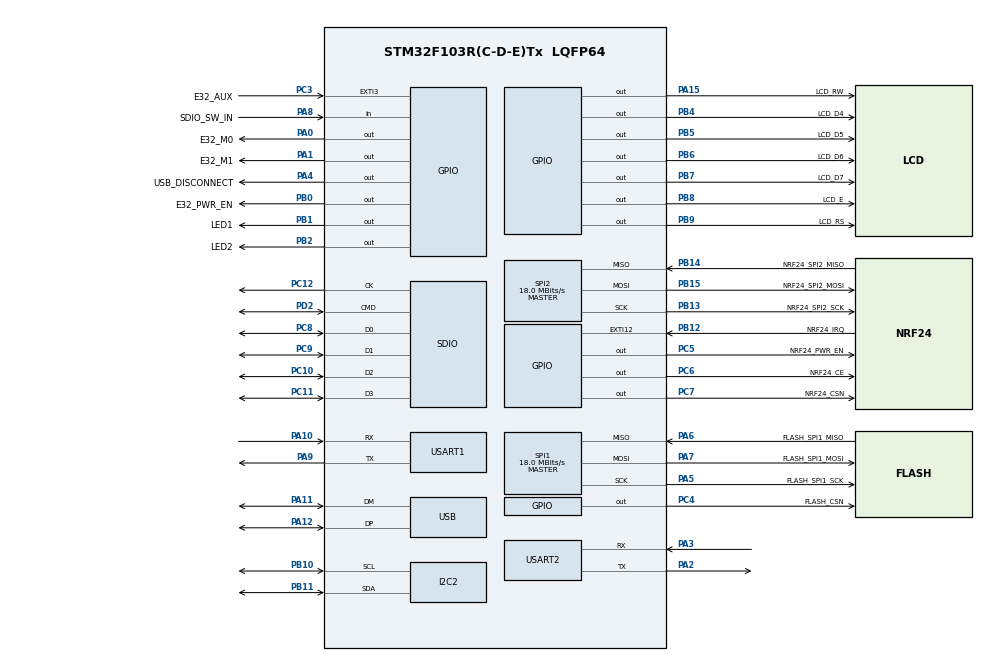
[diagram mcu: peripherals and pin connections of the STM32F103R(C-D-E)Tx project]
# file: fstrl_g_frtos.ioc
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Dma.MEMTOMEM.2.Direction=DMA_MEMORY_TO_MEMORY
Dma.MEMTOMEM.2.Instance=DMA1_Channel1
Dma.MEMTOMEM.2.MemDataAlignment=DMA_MDATAALIGN_WORD
Dma.MEMTOMEM.2.MemInc=DMA_MINC_ENABLE
Dma.MEMTOMEM.2.Mode=DMA_NORMAL
Dma.MEMTOMEM.2.PeriphDataAlignment=DMA_PDATAALIGN_WORD
Dma.MEMTOMEM.2.PeriphInc=DMA_PINC_ENABLE
Dma.MEMTOMEM.2.Priority=DMA_PRIORITY_MEDIUM
Dma.MEMTOMEM.3.Direction=DMA_MEMORY_TO_MEMORY
Dma.MEMTOMEM.3.Instance=DMA2_Channel1
Dma.MEMTOMEM.3.MemDataAlignment=DMA_MDATAALIGN_BYTE
Dma.MEMTOMEM.3.MemInc=DMA_MINC_ENABLE
Dma.MEMTOMEM.3.Mode=DMA_NORMAL
Dma.MEMTOMEM.3.PeriphDataAlignment=DMA_PDATAALIGN_BYTE
Dma.MEMTOMEM.3.PeriphInc=DMA_PINC_ENABLE
Dma.MEMTOMEM.3.Priority=DMA_PRIORITY_MEDIUM
Dma.Request0=SPI1_RX
Dma.Request1=SPI1_TX
Dma.Request2=MEMTOMEM
Dma.Request3=MEMTOMEM
Dma.Request4=USART1_RX
Dma.Request5=USART1_TX
Dma.Request6=USART2_RX
Dma.Request7=USART2_TX
Dma.Request8=SDIO
Dma.SDIO.8.Direction=DMA_PERIPH_TO_MEMORY
Dma.SDIO.8.Instance=DMA2_Channel4
Dma.SDIO.8.MemDataAlignment=DMA_MDATAALIGN_WORD
Dma.SDIO.8.MemInc=DMA_MINC_ENABLE
Dma.SDIO.8.Mode=DMA_NORMAL
Dma.SDIO.8.PeriphDataAlignment=DMA_PDATAALIGN_WORD
Dma.SDIO.8.PeriphInc=DMA_PINC_DISABLE
Dma.SDIO.8.Priority=DMA_PRIORITY_MEDIUM
Dma.SPI1_RX.0.Direction=DMA_PERIPH_TO_MEMORY
Dma.SPI1_RX.0.Instance=DMA1_Channel2
Dma.SPI1_RX.0.MemDataAlignment=DMA_MDATAALIGN_BYTE
Dma.SPI1_RX.0.MemInc=DMA_MINC_ENABLE
Dma.SPI1_RX.0.Mode=DMA_NORMAL
Dma.SPI1_RX.0.PeriphDataAlignment=DMA_PDATAALIGN_BYTE
Dma.SPI1_RX.0.PeriphInc=DMA_PINC_DISABLE
Dma.SPI1_RX.0.Priority=DMA_PRIORITY_VERY_HIGH
Dma.SPI1_TX.1.Direction=DMA_MEMORY_TO_PERIPH
Dma.SPI1_TX.1.Instance=DMA1_Channel3
Dma.SPI1_TX.1.MemDataAlignment=DMA_MDATAALIGN_BYTE
Dma.SPI1_TX.1.MemInc=DMA_MINC_ENABLE
Dma.SPI1_TX.1.Mode=DMA_NORMAL
Dma.SPI1_TX.1.PeriphDataAlignment=DMA_PDATAALIGN_BYTE
Dma.SPI1_TX.1.PeriphInc=DMA_PINC_DISABLE
Dma.SPI1_TX.1.Priority=DMA_PRIORITY_VERY_HIGH
Dma.USART1_RX.4.Direction=DMA_PERIPH_TO_MEMORY
Dma.USART1_RX.4.Instance=DMA1_Channel5
Dma.USART1_RX.4.MemDataAlignment=DMA_MDATAALIGN_BYTE
Dma.USART1_RX.4.MemInc=DMA_MINC_ENABLE
Dma.USART1_RX.4.Mode=DMA_NORMAL
Dma.USART1_RX.4.PeriphDataAlignment=DMA_PDATAALIGN_BYTE
Dma.USART1_RX.4.PeriphInc=DMA_PINC_DISABLE
Dma.USART1_RX.4.Priority=DMA_PRIORITY_LOW
Dma.USART1_TX.5.Direction=DMA_MEMORY_TO_PERIPH
Dma.USART1_TX.5.Instance=DMA1_Channel4
Dma.USART1_TX.5.MemDataAlignment=DMA_MDATAALIGN_BYTE
Dma.USART1_TX.5.MemInc=DMA_MINC_ENABLE
Dma.USART1_TX.5.Mode=DMA_NORMAL
Dma.USART1_TX.5.PeriphDataAlignment=DMA_PDATAALIGN_BYTE
Dma.USART1_TX.5.PeriphInc=DMA_PINC_DISABLE
Dma.USART1_TX.5.Priority=DMA_PRIORITY_LOW
Dma.USART2_RX.6.Direction=DMA_PERIPH_TO_MEMORY
Dma.USART2_RX.6.Instance=DMA1_Channel6
Dma.USART2_RX.6.MemDataAlignment=DMA_MDATAALIGN_BYTE
Dma.USART2_RX.6.MemInc=DMA_MINC_ENABLE
Dma.USART2_RX.6.Mode=DMA_NORMAL
Dma.USART2_RX.6.PeriphDataAlignment=DMA_PDATAALIGN_BYTE
Dma.USART2_RX.6.PeriphInc=DMA_PINC_DISABLE
Dma.USART2_RX.6.Priority=DMA_PRIORITY_LOW
Dma.USART2_TX.7.Direction=DMA_MEMORY_TO_PERIPH
Dma.USART2_TX.7.Instance=DMA1_Channel7
Dma.USART2_TX.7.MemDataAlignment=DMA_MDATAALIGN_BYTE
Dma.USART2_TX.7.MemInc=DMA_MINC_ENABLE
Dma.USART2_TX.7.Mode=DMA_NORMAL
Dma.USART2_TX.7.PeriphDataAlignment=DMA_PDATAALIGN_BYTE
Dma.USART2_TX.7.PeriphInc=DMA_PINC_DISABLE
Dma.USART2_TX.7.Priority=DMA_PRIORITY_LOW
FATFS.BSP.number=1
FATFS._FS_LOCK=4
FATFS._FS_RPATH=2
FATFS._USE_FIND=1
FATFS._VOLUMES=1
FATFS0.BSP.STBoard=false
FATFS0.BSP.api=Unknown
FATFS0.BSP.i2caddr=0
FATFS0.BSP.instance=PA8
FATFS0.BSP.ip=GPIO
FATFS0.BSP.mode=Input
FATFS0.BSP.name=Detect_SDIO
FATFS0.BSP.solution=PA8
FREERTOS.INCLUDE_eTaskGetState=1
FREERTOS.INCLUDE_pcTaskGetTaskName=1
FREERTOS.INCLUDE_uxTaskGetStackHighWaterMark=1
FREERTOS.INCLUDE_vTaskCleanUpResources=1
FREERTOS.INCLUDE_vTaskDelayUntil=1
FREERTOS.INCLUDE_xEventGroupSetBitFromISR=1
FREERTOS.INCLUDE_xQueueGetMutexHolder=1
FREERTOS.INCLUDE_xSemaphoreGetMutexHolder=1
FREERTOS.INCLUDE_xTaskAbortDelay=1
FREERTOS.INCLUDE_xTaskGetCurrentTaskHandle=1
FREERTOS.INCLUDE_xTaskGetHandle=1
FREERTOS.INCLUDE_xTimerPendFunctionCall=1
FREERTOS.MEMORY_ALLOCATION=2
FREERTOS.Mutexes01=mt_SPI1_free,Static,mt_SPI1_freeControlBlock;mt_SPI2_free,Static,mt_SPI2_freeControlBlock;mt_LCD_free,Static,mt_LCD_freeControlBlock;mt_UART1_free,Static,mt_UART1_freeControlBlock;mt_UART2_free,Static,mt_UART2_freeControlBlock;mt_NAND_FLASH,Static,mt_NAND_FLASHControlBlock
FREERTOS.Queues01=msgto_tsk_SpiNand_io,16,uint8_t,0,Static,msgto_SpiNand_wrkrBuffer,msgto_SpiNand_wrkrControlBlock;msgto_gkt_LCD,16,lcd_msg,0,Static,msgto_gkt_LCDBuffer,msgto_gkt_LCDControlBlock
FREERTOS.Tasks01=tsk_INIT_Periph,1,256,vStart_tsk_INIT_Periph,As weak,NULL,Static,tsk_INIT_PeriphBuffer,tsk_INIT_PeriphControlBlock;tsk_SPINand_io,0,1024,vStart_tsk_SPINand_io,As weak,NULL,Static,tsk_SPINand_ioBuffer,tsk_SPINand_ioControlBlock;tsk_LED1_blink,0,256,vStart_tsk_LEDx_blink,As weak,NULL,Static,tsk_LED1_blinkBuffer,tsk_LED1_blinkControlBlock;tsk_LED2_blink,0,256,vStart_tsk_LEDx_blink,As weak,1,Static,tsk_LED2_blinkBuffer,tsk_LED2_blinkControlBlock;gkt_LCD,0,256,vStart_gkt_LCD,As weak,NULL,Static,gkt_LCDBuffer,gkt_LCDControlBlock
FREERTOS.Timers01=tmTestTimer,tmTestTimer_clbck,osTimerPeriodic,Default,NULL,Static,tmTestTimerControlBlock
FREERTOS.configENABLE_BACKWARD_COMPATIBILITY=0
FREERTOS.configGENERATE_RUN_TIME_STATS=1
FREERTOS.configMAX_PRIORITIES=7
FREERTOS.configMAX_TASK_NAME_LEN=32
FREERTOS.configMINIMAL_STACK_SIZE=128
FREERTOS.configQUEUE_REGISTRY_SIZE=255
FREERTOS.configTIMER_TASK_PRIORITY=5
FREERTOS.configTOTAL_HEAP_SIZE=10240
FREERTOS.configUSE_APPLICATION_TASK_TAG=1
FREERTOS.configUSE_COUNTING_SEMAPHORES=1
FREERTOS.configUSE_MALLOC_FAILED_HOOK=1
FREERTOS.configUSE_STATS_FORMATTING_FUNCTIONS=1
FREERTOS.configUSE_TIMERS=1
FREERTOS.configUSE_TRACE_FACILITY=1
I2C2.I2C_Mode=I2C_Fast
Mcu.Family=STM32F1
Mcu.Name=STM32F103R(C-D-E)Tx
Mcu.Package=LQFP64
NVIC.DMA1_Channel1_IRQn=true\:5\:0\:false\:false\:true\:true\:true\:true
NVIC.DMA1_Channel2_IRQn=true\:5\:0\:false\:false\:true\:true\:false\:true
NVIC.DMA1_Channel3_IRQn=true\:5\:0\:false\:false\:true\:true\:false\:true
NVIC.DMA1_Channel4_IRQn=true\:5\:0\:false\:false\:true\:true\:false\:true
NVIC.DMA1_Channel5_IRQn=true\:5\:0\:false\:false\:true\:true\:false\:true
NVIC.DMA1_Channel6_IRQn=true\:5\:0\:false\:false\:true\:true\:false\:true
NVIC.DMA1_Channel7_IRQn=true\:5\:0\:false\:false\:true\:true\:false\:true
NVIC.DMA2_Channel1_IRQn=true\:5\:0\:false\:false\:true\:true\:true\:true
NVIC.DMA2_Channel4_5_IRQn=true\:5\:0\:false\:false\:true\:true\:false\:true
NVIC.PriorityGroup=NVIC_PRIORITYGROUP_4
NVIC.RCC_IRQn=true\:5\:0\:false\:false\:true\:true\:true\:false
NVIC.SDIO_IRQn=true\:5\:0\:false\:false\:true\:true\:true\:true
NVIC.TIM6_IRQn=true\:0\:0\:false\:false\:true\:false\:true\:true
NVIC.TIM7_IRQn=true\:5\:0\:true\:false\:true\:true\:true\:true
NVIC.TimeBase=TIM6_IRQn
NVIC.TimeBaseIP=TIM6
NVIC.USART1_IRQn=true\:5\:0\:true\:false\:true\:true\:true\:true
NVIC.USART2_IRQn=true\:5\:0\:true\:false\:true\:true\:true\:true
NVIC.USB_LP_CAN1_RX0_IRQn=true\:5\:0\:false\:false\:true\:true\:false\:true
PA0-WKUP.GPIO_Label=E32_M0
PA0-WKUP.GPIO_ModeDefaultOutputPP=GPIO_MODE_OUTPUT_PP
PA0-WKUP.GPIO_PuPd=GPIO_NOPULL
PA0-WKUP.GPIO_Speed=GPIO_SPEED_FREQ_LOW
PA0-WKUP.PinState=GPIO_PIN_RESET
PA0-WKUP.Signal=GPIO_Output
PA1.GPIO_Label=E32_M1
PA1.GPIO_ModeDefaultOutputPP=GPIO_MODE_OUTPUT_PP
PA1.GPIO_PuPd=GPIO_NOPULL
PA1.GPIO_Speed=GPIO_SPEED_FREQ_LOW
PA1.PinState=GPIO_PIN_RESET
PA1.Signal=GPIO_Output
PA10.Mode=Asynchronous
PA10.Signal=USART1_RX
PA11.Mode=Device
PA11.Signal=USB_DM
PA12.Mode=Device
PA12.Signal=USB_DP
PA13.Mode=Trace_Asynchronous_SW
PA13.Signal=SYS_JTMS-SWDIO
PA14.Mode=Trace_Asynchronous_SW
PA14.Signal=SYS_JTCK-SWCLK
PA15.GPIO_Label=LCD_RW
PA15.GPIO_ModeDefaultOutputPP=GPIO_MODE_OUTPUT_PP
PA15.GPIO_PuPd=GPIO_NOPULL
PA15.GPIO_Speed=GPIO_SPEED_FREQ_HIGH
PA15.PinState=GPIO_PIN_RESET
PA15.Signal=GPIO_Output
PA2.GPIO_Mode=GPIO_MODE_AF_PP
PA2.GPIO_Speed=GPIO_SPEED_FREQ_HIGH
PA2.Mode=Asynchronous
PA2.Signal=USART2_TX
PA3.GPIO_Mode=GPIO_MODE_INPUT
PA3.GPIO_PuPd=GPIO_NOPULL
PA3.Mode=Asynchronous
PA3.Signal=USART2_RX
PA4.GPIO_Label=USB_DISCONNECT
PA4.GPIO_ModeDefaultOutputPP=GPIO_MODE_OUTPUT_OD
PA4.GPIO_PuPd=GPIO_PULLUP
PA4.GPIO_Speed=GPIO_SPEED_FREQ_HIGH
PA4.PinState=GPIO_PIN_SET
PA4.Signal=GPIO_Output
PA5.GPIO_Label=FLASH_SPI1_SCK
PA5.GPIO_Mode=GPIO_MODE_AF_PP
PA5.GPIO_Speed=GPIO_SPEED_FREQ_HIGH
PA5.Mode=Full_Duplex_Master
PA5.Signal=SPI1_SCK
PA6.GPIO_Label=FLASH_SPI1_MISO
PA6.GPIO_Mode=GPIO_MODE_INPUT
PA6.GPIO_PuPd=GPIO_NOPULL
PA6.Mode=Full_Duplex_Master
PA6.Signal=SPI1_MISO
PA7.GPIO_Label=FLASH_SPI1_MOSI
PA7.GPIO_Mode=GPIO_MODE_AF_PP
PA7.GPIO_Speed=GPIO_SPEED_FREQ_HIGH
PA7.Mode=Full_Duplex_Master
PA7.Signal=SPI1_MOSI
PA8.GPIO_Label=SDIO_SW_IN
PA8.GPIO_Mode=GPIO_MODE_INPUT
PA8.GPIO_PuPd=GPIO_PULLUP
PA8.Signal=GPIO_Input
PA9.Mode=Asynchronous
PA9.Signal=USART1_TX
PB0.GPIO_Label=E32_PWR_EN
PB0.GPIO_ModeDefaultOutputPP=GPIO_MODE_OUTPUT_PP
PB0.GPIO_PuPd=GPIO_NOPULL
PB0.GPIO_Speed=GPIO_SPEED_FREQ_LOW
PB0.PinState=GPIO_PIN_RESET
PB0.Signal=GPIO_Output
PB1.GPIO_Label=LED1
PB1.GPIO_ModeDefaultOutputPP=GPIO_MODE_OUTPUT_PP
PB1.GPIO_PuPd=GPIO_NOPULL
PB1.GPIO_Speed=GPIO_SPEED_FREQ_LOW
PB1.PinState=GPIO_PIN_SET
PB1.Signal=GPIO_Output
PB10.Mode=I2C
PB10.Signal=I2C2_SCL
PB11.Mode=I2C
PB11.Signal=I2C2_SDA
PB12.GPIO_Label=NRF24_IRQ
PB12.GPIO_ModeDefaultEXTI=GPIO_MODE_IT_RISING
PB12.GPIO_PuPd=GPIO_NOPULL
PB12.Signal=GPXTI12
PB13.GPIO_Label=NRF24_SPI2_SCK
PB13.GPIO_Mode=GPIO_MODE_AF_PP
PB13.GPIO_Speed=GPIO_SPEED_FREQ_HIGH
PB13.Mode=Full_Duplex_Master
PB13.Signal=SPI2_SCK
PB14.GPIO_Label=NRF24_SPI2_MISO
PB14.GPIO_Mode=GPIO_MODE_INPUT
PB14.GPIO_PuPd=GPIO_NOPULL
PB14.Mode=Full_Duplex_Master
PB14.Signal=SPI2_MISO
PB15.GPIO_Label=NRF24_SPI2_MOSI
PB15.GPIO_Mode=GPIO_MODE_AF_PP
PB15.GPIO_Speed=GPIO_SPEED_FREQ_HIGH
PB15.Mode=Full_Duplex_Master
PB15.Signal=SPI2_MOSI
PB2.GPIO_Label=LED2
PB2.GPIO_ModeDefaultOutputPP=GPIO_MODE_OUTPUT_PP
PB2.GPIO_PuPd=GPIO_NOPULL
PB2.GPIO_Speed=GPIO_SPEED_FREQ_LOW
PB2.PinState=GPIO_PIN_RESET
PB2.Signal=GPIO_Output
PB3.Mode=Trace_Asynchronous_SW
PB3.Signal=SYS_JTDO-TRACESWO
PB4.GPIO_Label=LCD_D4
PB4.GPIO_ModeDefaultOutputPP=GPIO_MODE_OUTPUT_PP
PB4.GPIO_PuPd=GPIO_NOPULL
PB4.GPIO_Speed=GPIO_SPEED_FREQ_HIGH
PB4.PinState=GPIO_PIN_RESET
PB4.Signal=GPIO_Output
PB5.GPIO_Label=LCD_D5
PB5.GPIO_ModeDefaultOutputPP=GPIO_MODE_OUTPUT_PP
PB5.GPIO_PuPd=GPIO_NOPULL
PB5.GPIO_Speed=GPIO_SPEED_FREQ_HIGH
PB5.PinState=GPIO_PIN_RESET
PB5.Signal=GPIO_Output
PB6.GPIO_Label=LCD_D6
PB6.GPIO_ModeDefaultOutputPP=GPIO_MODE_OUTPUT_PP
PB6.GPIO_PuPd=GPIO_NOPULL
PB6.GPIO_Speed=GPIO_SPEED_FREQ_HIGH
PB6.PinState=GPIO_PIN_RESET
PB6.Signal=GPIO_Output
PB7.GPIO_Label=LCD_D7
PB7.GPIO_ModeDefaultOutputPP=GPIO_MODE_OUTPUT_PP
PB7.GPIO_PuPd=GPIO_NOPULL
PB7.GPIO_Speed=GPIO_SPEED_FREQ_HIGH
PB7.PinState=GPIO_PIN_RESET
PB7.Signal=GPIO_Output
PB8.GPIO_Label=LCD_E
PB8.GPIO_ModeDefaultOutputPP=GPIO_MODE_OUTPUT_PP
PB8.GPIO_PuPd=GPIO_NOPULL
PB8.GPIO_Speed=GPIO_SPEED_FREQ_HIGH
PB8.PinState=GPIO_PIN_RESET
PB8.Signal=GPIO_Output
PB9.GPIO_Label=LCD_RS
PB9.GPIO_ModeDefaultOutputPP=GPIO_MODE_OUTPUT_PP
PB9.GPIO_PuPd=GPIO_NOPULL
PB9.GPIO_Speed=GPIO_SPEED_FREQ_HIGH
PB9.PinState=GPIO_PIN_RESET
PB9.Signal=GPIO_Output
PC10.Mode=SD_4_bits_Wide_bus
PC10.Signal=SDIO_D2
PC11.Mode=SD_4_bits_Wide_bus
PC11.Signal=SDIO_D3
PC12.Mode=SD_4_bits_Wide_bus
PC12.Signal=SDIO_CK
PC14-OSC32_IN.Mode=LSE-External-Oscillator
PC14-OSC32_IN.Signal=RCC_OSC32_IN
PC15-OSC32_OUT.Mode=LSE-External-Oscillator
PC15-OSC32_OUT.Signal=RCC_OSC32_OUT
PC3.GPIO_Label=E32_AUX
PC3.GPIO_ModeDefaultEXTI=GPIO_MODE_IT_RISING
PC3.GPIO_PuPd=GPIO_NOPULL
PC3.Signal=GPXTI3
PC4.GPIO_Label=FLASH_CSN
PC4.GPIO_ModeDefaultOutputPP=GPIO_MODE_OUTPUT_PP
PC4.GPIO_PuPd=GPIO_NOPULL
PC4.GPIO_Speed=GPIO_SPEED_FREQ_HIGH
PC4.PinState=GPIO_PIN_SET
PC4.Signal=GPIO_Output
PC5.GPIO_Label=NRF24_PWR_EN
PC5.GPIO_ModeDefaultOutputPP=GPIO_MODE_OUTPUT_PP
PC5.GPIO_PuPd=GPIO_NOPULL
PC5.GPIO_Speed=GPIO_SPEED_FREQ_MEDIUM
PC5.PinState=GPIO_PIN_RESET
PC5.Signal=GPIO_Output
PC6.GPIO_Label=NRF24_CE
PC6.GPIO_ModeDefaultOutputPP=GPIO_MODE_OUTPUT_PP
PC6.GPIO_PuPd=GPIO_NOPULL
PC6.GPIO_Speed=GPIO_SPEED_FREQ_MEDIUM
PC6.PinState=GPIO_PIN_SET
PC6.Signal=GPIO_Output
PC7.GPIO_Label=NRF24_CSN
PC7.GPIO_ModeDefaultOutputPP=GPIO_MODE_OUTPUT_PP
PC7.GPIO_PuPd=GPIO_NOPULL
PC7.GPIO_Speed=GPIO_SPEED_FREQ_MEDIUM
PC7.PinState=GPIO_PIN_RESET
PC7.Signal=GPIO_Output
PC8.Mode=SD_4_bits_Wide_bus
PC8.Signal=SDIO_D0
PC9.Mode=SD_4_bits_Wide_bus
PC9.Signal=SDIO_D1
PD0-OSC_IN.Mode=HSE-External-Oscillator
PD0-OSC_IN.Signal=RCC_OSC_IN
PD1-OSC_OUT.Mode=HSE-External-Oscillator
PD1-OSC_OUT.Signal=RCC_OSC_OUT
PD2.Mode=SD_4_bits_Wide_bus
PD2.Signal=SDIO_CMD
ProjectManager.HeapSize=0x2000
ProjectManager.StackSize=0x1000
ProjectManager.TargetToolchain=STM32CubeIDE
RCC.AHBFreq_Value=72000000
RCC.APB1CLKDivider=RCC_HCLK_DIV2
RCC.APB1Freq_Value=36000000
RCC.APB1TimFreq_Value=72000000
RCC.APB2Freq_Value=72000000
RCC.APB2TimFreq_Value=72000000
RCC.EnbaleCSS=true
RCC.HCLKFreq_Value=72000000
RCC.HSE_VALUE=12000000
RCC.PLLMUL=RCC_PLL_MUL6
RCC.PLLSourceVirtual=RCC_PLLSOURCE_HSE
RCC.RTCClockSelection=RCC_RTCCLKSOURCE_LSE
RCC.SYSCLKFreq_VALUE=72000000
RCC.SYSCLKSource=RCC_SYSCLKSOURCE_PLLCLK
RCC.USBFreq_Value=48000000
RCC.USBPrescaler=RCC_USBCLKSOURCE_PLL_DIV1_5
RTC.Date=19
RTC.Month=RTC_MONTH_AUGUST
RTC.OutPut=RTC_OUTPUTSOURCE_SECOND
RTC.WeekDay=RTC_WEEKDAY_FRIDAY
RTC.Year=14
SDIO.ClockBypass=SDIO_CLOCK_BYPASS_DISABLE
SDIO.ClockDiv=4
SDIO.ClockPowerSave=SDIO_CLOCK_POWER_SAVE_DISABLE
SDIO.HardwareFlowControl=SDIO_HARDWARE_FLOW_CONTROL_DISABLE
SPI1.BaudRatePrescaler=SPI_BAUDRATEPRESCALER_4
SPI1.CalculateBaudRate=18.0 MBits/s
SPI1.Direction=SPI_DIRECTION_2LINES
SPI1.Mode=SPI_MODE_MASTER
SPI1.VirtualType=VM_MASTER
SPI2.BaudRatePrescaler=SPI_BAUDRATEPRESCALER_2
SPI2.CalculateBaudRate=18.0 MBits/s
SPI2.Direction=SPI_DIRECTION_2LINES
SPI2.Mode=SPI_MODE_MASTER
SPI2.VirtualType=VM_MASTER
TIM7.Period=0xFFFF
TIM7.Prescaler=((SystemCoreClock/1000000) - 1)
TIM7.TIM_MasterOutputTrigger=TIM_TRGO_UPDATE
USART1.VirtualMode=VM_ASYNC
USART2.VirtualMode=VM_ASYNC
USB.low_power_enable=DISABLE
USB.lpm_enable=DISABLE
USB_DEVICE.CLASS_NAME_FS=MSC
USB_DEVICE.MANUFACTURER_STRING=FSTRL
USB_DEVICE.PRODUCT_STRING_MSC_FS=FSTRL Mass Storage
USB_DEVICE.USBD_DEBUG_LEVEL=0
USB_DEVICE.USBD_MAX_NUM_CONFIGURATION=1
USB_DEVICE.USBD_MAX_NUM_INTERFACES=1
USB_DEVICE.USBD_SELF_POWERED=0
USB_DEVICE.VirtualMode=Msc
USB_DEVICE.VirtualModeFS=Msc_FS
VP_CRC_VS_CRC.Mode=CRC_Activate
VP_FATFS_VS_SDIO.Mode=SDIO
VP_FREERTOS_VS_CMSIS_V1.Mode=CMSIS_V1
VP_RTC_VS_RTC_Activate.Mode=RTC_Enabled
VP_RTC_VS_RTC_Calendar.Mode=RTC_Calendar
VP_SYS_VS_tim6.Mode=TIM6
VP_TIM7_VS_ClockSourceINT.Mode=Enable_Timer
VP_TIM7_VS_OPM.Mode=OPM_bit
VP_USB_DEVICE_VS_USB_DEVICE_MSC_FS.Mode=MSC_FS
board=custom

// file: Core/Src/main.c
/* USER CODE BEGIN Header */
/**
  ******************************************************************************
  * @file           : main.c
  * @brief          : Main program body
  ******************************************************************************
  * @attention
  *
  * <h2><center>&copy; Copyright (c) 2019 STMicroelectronics.
  * All rights reserved.</center></h2>
  *
  * This software component is licensed by ST under Ultimate Liberty license
  * SLA0044, the "License"; You may not use this file except in compliance with
  * the License. You may obtain a copy of the License at:
  *                             www.st.com/SLA0044
  *
  ******************************************************************************
  */
/* USER CODE END Header */

#include "main.h"
#include "cmsis_os.h"
#include "crc.h"
#include "dma.h"
#include "fatfs.h"
#include "i2c.h"
#include "rtc.h"
#include "sdio.h"
#include "spi.h"
#include "tim.h"
#include "usart.h"
#include "usb_device.h"
#include "gpio.h"

void SystemClock_Config(void);
void MX_FREERTOS_Init(void);

int main(void)
{
  /* USER CODE BEGIN 1 */
//tt
  /* USER CODE END 1 */

  /* MCU Configuration--------------------------------------------------------*/

  /* Reset of all peripherals, Initializes the Flash interface and the Systick. */
  HAL_Init();

  /* Configure the system clock */
  SystemClock_Config();

  /* USER CODE BEGIN SysInit */
  //LL_SYSTICK_EnableIT();
  /* USER CODE END SysInit */

  /* Initialize all configured peripherals */
  MX_GPIO_Init();
  MX_DMA_Init();
  MX_SPI2_Init();
  MX_SDIO_SD_Init();
  MX_USART1_UART_Init();
  MX_USART2_UART_Init();
  MX_SPI1_Init();
  MX_I2C2_Init();
  MX_CRC_Init();
  MX_TIM7_Init();
  MX_RTC_Init();
  /* USER CODE BEGIN 2 */
  DWT_Delay_Init();
  USB_PIN_DISCONNECT()

  /* USER CODE END 2 */

  /* Call init function for freertos objects (in freertos.c) */
  MX_FREERTOS_Init();

  /* Start scheduler */
  osKernelStart();

  /* We should never get here as control is now taken by the scheduler */

  /* Infinite loop */
  while (1)
  {

  }
}

void SystemClock_Config(void)
{
  LL_FLASH_SetLatency(LL_FLASH_LATENCY_2);

   if(LL_FLASH_GetLatency() != LL_FLASH_LATENCY_2)
  {
    Error_Handler();
  }
  LL_RCC_HSE_Enable();

   /* Wait till HSE is ready */
  while(LL_RCC_HSE_IsReady() != 1)
  {

  }
  LL_PWR_EnableBkUpAccess();
  LL_RCC_ForceBackupDomainReset();
  LL_RCC_ReleaseBackupDomainReset();
  LL_RCC_LSE_Enable();

   /* Wait till LSE is ready */
  while(LL_RCC_LSE_IsReady() != 1)
  {

  }
  LL_RCC_SetRTCClockSource(LL_RCC_RTC_CLKSOURCE_LSE);
  LL_RCC_EnableRTC();
  LL_RCC_HSE_EnableCSS();
  LL_RCC_PLL_ConfigDomain_SYS(LL_RCC_PLLSOURCE_HSE_DIV_1, LL_RCC_PLL_MUL_6);
  LL_RCC_PLL_Enable();

   /* Wait till PLL is ready */
  while(LL_RCC_PLL_IsReady() != 1)
  {

  }
  LL_RCC_SetAHBPrescaler(LL_RCC_SYSCLK_DIV_1);
  LL_RCC_SetAPB1Prescaler(LL_RCC_APB1_DIV_2);
  LL_RCC_SetAPB2Prescaler(LL_RCC_APB2_DIV_1);
  LL_RCC_SetSysClkSource(LL_RCC_SYS_CLKSOURCE_PLL);

   /* Wait till System clock is ready */
  while(LL_RCC_GetSysClkSource() != LL_RCC_SYS_CLKSOURCE_STATUS_PLL)
  {

  }
  LL_Init1msTick(72000000);
  LL_SYSTICK_SetClkSource(LL_SYSTICK_CLKSOURCE_HCLK);
  LL_SetSystemCoreClock(72000000);
  LL_RCC_SetUSBClockSource(LL_RCC_USB_CLKSOURCE_PLL_DIV_1_5);
}

void HAL_TIM_PeriodElapsedCallback(TIM_HandleTypeDef *htim)
{
  if (htim->Instance == TIM6) {
    HAL_IncTick();
  }
}

void Error_Handler(void)
{
}

/************************ (C) COPYRIGHT STMicroelectronics *****END OF FILE****/

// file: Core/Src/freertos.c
/* USER CODE BEGIN Header */
/**
  ******************************************************************************
  * File Name          : freertos.c
  * Description        : Code for freertos applications
  ******************************************************************************
  * @attention
  *
  * <h2><center>&copy; Copyright (c) 2019 STMicroelectronics.
  * All rights reserved.</center></h2>
  *
  * This software component is licensed by ST under Ultimate Liberty license
  * SLA0044, the "License"; You may not use this file except in compliance with
  * the License. You may obtain a copy of the License at:
  *                             www.st.com/SLA0044
  *
  ******************************************************************************
  */
/* USER CODE END Header */

#include "FreeRTOS.h"
#include "task.h"
#include "main.h"
#include "cmsis_os.h"

/* USER CODE BEGIN Includes */
#include "gkt_LCD.h"
/* USER CODE END Includes */

osThreadId tsk_INIT_PeriphHandle;
uint32_t tsk_INIT_PeriphBuffer[ 256 ];
osStaticThreadDef_t tsk_INIT_PeriphControlBlock;
osThreadId tsk_SPINand_ioHandle;
uint32_t tsk_SPINand_ioBuffer[ 1024 ];
osStaticThreadDef_t tsk_SPINand_ioControlBlock;
osThreadId tsk_LED1_blinkHandle;
uint32_t tsk_LED1_blinkBuffer[ 256 ];
osStaticThreadDef_t tsk_LED1_blinkControlBlock;
osThreadId tsk_LED2_blinkHandle;
uint32_t tsk_LED2_blinkBuffer[ 256 ];
osStaticThreadDef_t tsk_LED2_blinkControlBlock;
osThreadId gkt_LCDHandle;
uint32_t gkt_LCDBuffer[ 256 ];
osStaticThreadDef_t gkt_LCDControlBlock;
osMessageQId msgto_tsk_SpiNand_ioHandle;
uint8_t msgto_SpiNand_wrkrBuffer[ 16 * sizeof( uint8_t ) ];
osStaticMessageQDef_t msgto_SpiNand_wrkrControlBlock;
osMessageQId msgto_gkt_LCDHandle;
uint8_t msgto_gkt_LCDBuffer[ 16 * sizeof( lcd_msg ) ];
osStaticMessageQDef_t msgto_gkt_LCDControlBlock;
osTimerId tmTestTimerHandle;
osStaticTimerDef_t tmTestTimerControlBlock;
osMutexId mt_SPI1_freeHandle;
osStaticMutexDef_t mt_SPI1_freeControlBlock;
osMutexId mt_SPI2_freeHandle;
osStaticMutexDef_t mt_SPI2_freeControlBlock;
osMutexId mt_LCD_freeHandle;
osStaticMutexDef_t mt_LCD_freeControlBlock;
osMutexId mt_UART1_freeHandle;
osStaticMutexDef_t mt_UART1_freeControlBlock;
osMutexId mt_UART2_freeHandle;
osStaticMutexDef_t mt_UART2_freeControlBlock;
osMutexId mt_NAND_FLASHHandle;
osStaticMutexDef_t mt_NAND_FLASHControlBlock;

void vStart_tsk_INIT_Periph(const void * argument);
void vStart_tsk_SPINand_io(const void * argument);
void vStart_tsk_LEDx_blink(const void * argument);
void vStart_gkt_LCD(const void * argument);
void tmTestTimer_clbck(const void * argument);

extern void MX_USB_DEVICE_Init(void);
extern void MX_FATFS_Init(void);
void MX_FREERTOS_Init(void); /* (MISRA C 2004 rule 8.1) */

/* GetIdleTaskMemory prototype (linked to static allocation support) */
void vApplicationGetIdleTaskMemory( StaticTask_t **ppxIdleTaskTCBBuffer, StackType_t **ppxIdleTaskStackBuffer, uint32_t *pulIdleTaskStackSize );

/* GetTimerTaskMemory prototype (linked to static allocation support) */
void vApplicationGetTimerTaskMemory( StaticTask_t **ppxTimerTaskTCBBuffer, StackType_t **ppxTimerTaskStackBuffer, uint32_t *pulTimerTaskStackSize );

/* Hook prototypes */
void configureTimerForRunTimeStats(void);
unsigned long getRunTimeCounterValue(void);
void vApplicationMallocFailedHook(void);

/* USER CODE BEGIN 1 */
/* Functions needed when configGENERATE_RUN_TIME_STATS is on */
__weak void configureTimerForRunTimeStats(void)
{

}

__weak unsigned long getRunTimeCounterValue(void)
{
return 0;
}
/* USER CODE END 1 */

/* USER CODE BEGIN 5 */
__weak void vApplicationMallocFailedHook(void)
{
   /* vApplicationMallocFailedHook() will only be called if
   configUSE_MALLOC_FAILED_HOOK is set to 1 in FreeRTOSConfig.h. It is a hook
   function that will get called if a call to pvPortMalloc() fails.
   pvPortMalloc() is called internally by the kernel whenever a task, queue,
   timer or semaphore is created. It is also called by various parts of the
   demo application. If heap_1.c or heap_2.c are used, then the size of the
   heap available to pvPortMalloc() is defined by configTOTAL_HEAP_SIZE in
   FreeRTOSConfig.h, and the xPortGetFreeHeapSize() API function can be used
   to query the size of free heap space that remains (although it does not
   provide information on how the remaining heap might be fragmented). */
}
/* USER CODE END 5 */

/* USER CODE BEGIN GET_IDLE_TASK_MEMORY */
static StaticTask_t xIdleTaskTCBBuffer;
static StackType_t xIdleStack[configMINIMAL_STACK_SIZE];

void vApplicationGetIdleTaskMemory( StaticTask_t **ppxIdleTaskTCBBuffer, StackType_t **ppxIdleTaskStackBuffer, uint32_t *pulIdleTaskStackSize )
{
  *ppxIdleTaskTCBBuffer   = &xIdleTaskTCBBuffer;
  *ppxIdleTaskStackBuffer = &xIdleStack[0];
  *pulIdleTaskStackSize   = configMINIMAL_STACK_SIZE;
  /* place for user code */
}
/* USER CODE END GET_IDLE_TASK_MEMORY */

/* USER CODE BEGIN GET_TIMER_TASK_MEMORY */
static StaticTask_t xTimerTaskTCBBuffer;
static StackType_t xTimerStack[configTIMER_TASK_STACK_DEPTH];

void vApplicationGetTimerTaskMemory( StaticTask_t **ppxTimerTaskTCBBuffer, StackType_t **ppxTimerTaskStackBuffer, uint32_t *pulTimerTaskStackSize )
{
  *ppxTimerTaskTCBBuffer = &xTimerTaskTCBBuffer;
  *ppxTimerTaskStackBuffer = &xTimerStack[0];
  *pulTimerTaskStackSize = configTIMER_TASK_STACK_DEPTH;
  /* place for user code */
}
/* USER CODE END GET_TIMER_TASK_MEMORY */

void MX_FREERTOS_Init(void) {

  /* Create the mutex(es) */
  /* definition and creation of mt_SPI1_free */
  osMutexStaticDef(mt_SPI1_free, &mt_SPI1_freeControlBlock);
  mt_SPI1_freeHandle = osMutexCreate(osMutex(mt_SPI1_free));

  /* definition and creation of mt_SPI2_free */
  osMutexStaticDef(mt_SPI2_free, &mt_SPI2_freeControlBlock);
  mt_SPI2_freeHandle = osMutexCreate(osMutex(mt_SPI2_free));

  /* definition and creation of mt_LCD_free */
  osMutexStaticDef(mt_LCD_free, &mt_LCD_freeControlBlock);
  mt_LCD_freeHandle = osMutexCreate(osMutex(mt_LCD_free));

  /* definition and creation of mt_UART1_free */
  osMutexStaticDef(mt_UART1_free, &mt_UART1_freeControlBlock);
  mt_UART1_freeHandle = osMutexCreate(osMutex(mt_UART1_free));

  /* definition and creation of mt_UART2_free */
  osMutexStaticDef(mt_UART2_free, &mt_UART2_freeControlBlock);
  mt_UART2_freeHandle = osMutexCreate(osMutex(mt_UART2_free));

  /* definition and creation of mt_NAND_FLASH */
  osMutexStaticDef(mt_NAND_FLASH, &mt_NAND_FLASHControlBlock);
  mt_NAND_FLASHHandle = osMutexCreate(osMutex(mt_NAND_FLASH));

  /* Create the timer(s) */
  /* definition and creation of tmTestTimer */
  osTimerStaticDef(tmTestTimer, tmTestTimer_clbck, &tmTestTimerControlBlock);
  tmTestTimerHandle = osTimerCreate(osTimer(tmTestTimer), osTimerPeriodic, NULL);

  /* Create the queue(s) */
  /* definition and creation of msgto_tsk_SpiNand_io */
  osMessageQStaticDef(msgto_tsk_SpiNand_io, 16, uint8_t, msgto_SpiNand_wrkrBuffer, &msgto_SpiNand_wrkrControlBlock);
  msgto_tsk_SpiNand_ioHandle = osMessageCreate(osMessageQ(msgto_tsk_SpiNand_io), NULL);

  /* definition and creation of msgto_gkt_LCD */
  osMessageQStaticDef(msgto_gkt_LCD, 16, lcd_msg, msgto_gkt_LCDBuffer, &msgto_gkt_LCDControlBlock);
  msgto_gkt_LCDHandle = osMessageCreate(osMessageQ(msgto_gkt_LCD), NULL);

  /* Create the thread(s) */
  /* definition and creation of tsk_INIT_Periph */
  osThreadStaticDef(tsk_INIT_Periph, vStart_tsk_INIT_Periph, osPriorityAboveNormal, 0, 256, tsk_INIT_PeriphBuffer, &tsk_INIT_PeriphControlBlock);
  tsk_INIT_PeriphHandle = osThreadCreate(osThread(tsk_INIT_Periph), NULL);

  /* definition and creation of tsk_SPINand_io */
  osThreadStaticDef(tsk_SPINand_io, vStart_tsk_SPINand_io, osPriorityNormal, 0, 1024, tsk_SPINand_ioBuffer, &tsk_SPINand_ioControlBlock);
  tsk_SPINand_ioHandle = osThreadCreate(osThread(tsk_SPINand_io), NULL);

  /* definition and creation of tsk_LED1_blink */
  osThreadStaticDef(tsk_LED1_blink, vStart_tsk_LEDx_blink, osPriorityNormal, 0, 256, tsk_LED1_blinkBuffer, &tsk_LED1_blinkControlBlock);
  tsk_LED1_blinkHandle = osThreadCreate(osThread(tsk_LED1_blink), NULL);

  /* definition and creation of tsk_LED2_blink */
  osThreadStaticDef(tsk_LED2_blink, vStart_tsk_LEDx_blink, osPriorityNormal, 0, 256, tsk_LED2_blinkBuffer, &tsk_LED2_blinkControlBlock);
  tsk_LED2_blinkHandle = osThreadCreate(osThread(tsk_LED2_blink), (void*) 1);

  /* definition and creation of gkt_LCD */
  osThreadStaticDef(gkt_LCD, vStart_gkt_LCD, osPriorityNormal, 0, 256, gkt_LCDBuffer, &gkt_LCDControlBlock);
  gkt_LCDHandle = osThreadCreate(osThread(gkt_LCD), NULL);

}

__weak void vStart_tsk_INIT_Periph(const void * argument)
{
  /* init code for USB_DEVICE */
  MX_USB_DEVICE_Init();

  /* init code for FATFS */
  MX_FATFS_Init();

  for(;;)
  {
    osDelay(1);
  }
}

__weak void vStart_tsk_SPINand_io(const void * argument)
{
  for(;;)
  {
    osDelay(1);
  }
}

__weak void vStart_tsk_LEDx_blink(const void * argument)
{
  for(;;)
  {
    osDelay(1);
  }
}

__weak void vStart_gkt_LCD(const void * argument)
{
  for(;;)
  {
    osDelay(1);
  }
}

/* tmTestTimer_clbck function */
void tmTestTimer_clbck(const void * argument)
{
}

/************************ (C) COPYRIGHT STMicroelectronics *****END OF FILE****/
